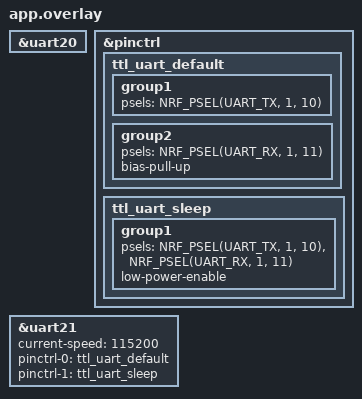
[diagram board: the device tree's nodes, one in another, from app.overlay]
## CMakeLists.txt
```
cmake_minimum_required(VERSION 3.20.0)
find_package(Zephyr REQUIRED HINTS $ENV{ZEPHYR_BASE})

project(uart_ttl_test)

target_sources(app PRIVATE src/main.c)
```

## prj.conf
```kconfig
CONFIG_SERIAL=y
CONFIG_UART_NRFX=y
CONFIG_PRINTK=y
CONFIG_CONSOLE=y
CONFIG_UART_CONSOLE=y
```

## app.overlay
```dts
#include <zephyr/dt-bindings/pinctrl/nrf-pinctrl.h>

/* Keep the existing UART available for the USB console. */
&uart20 {
    status = "okay";
};

/* Assign separate pins for the external TTL adapter. */
&pinctrl {
    ttl_uart_default: ttl_uart_default {
        group1 {
            psels = <NRF_PSEL(UART_TX, 1, 10)>;
        };

        group2 {
            psels = <NRF_PSEL(UART_RX, 1, 11)>;
            bias-pull-up;
        };
    };

    ttl_uart_sleep: ttl_uart_sleep {
        group1 {
            psels = <NRF_PSEL(UART_TX, 1, 10)>,
                    <NRF_PSEL(UART_RX, 1, 11)>;
            low-power-enable;
        };
    };
};

&uart21 {
    status = "okay";
    current-speed = <115200>;

    pinctrl-0 = <&ttl_uart_default>;
    pinctrl-1 = <&ttl_uart_sleep>;
    pinctrl-names = "default", "sleep";
};
```

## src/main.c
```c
#include <zephyr/kernel.h>
#include <zephyr/device.h>
#include <zephyr/devicetree.h>
#include <zephyr/drivers/uart.h>
#include <stdio.h>
#include <stdint.h>

#define UART_NODE DT_NODELABEL(uart21)

static const struct device *uart_dev =
    DEVICE_DT_GET(UART_NODE);

int main(void)
{
    uint8_t received_char;

    if (!device_is_ready(uart_dev))
    {
        printk("UART20 device not ready!\n");
        return 0;
    }

    printk("UART20 RX TEST STARTED - 9600 baud\n");

    while (1)
    {
        if (uart_poll_in(uart_dev, &received_char) == 0)
        {
            printk("Received: 0x%02X | ASCII: %c\n",
                   received_char,
                   (received_char >= 32 && received_char <= 126)
                       ? received_char : '.');
        }

        k_sleep(K_MSEC(1));
    }

    return 0;
}
```
